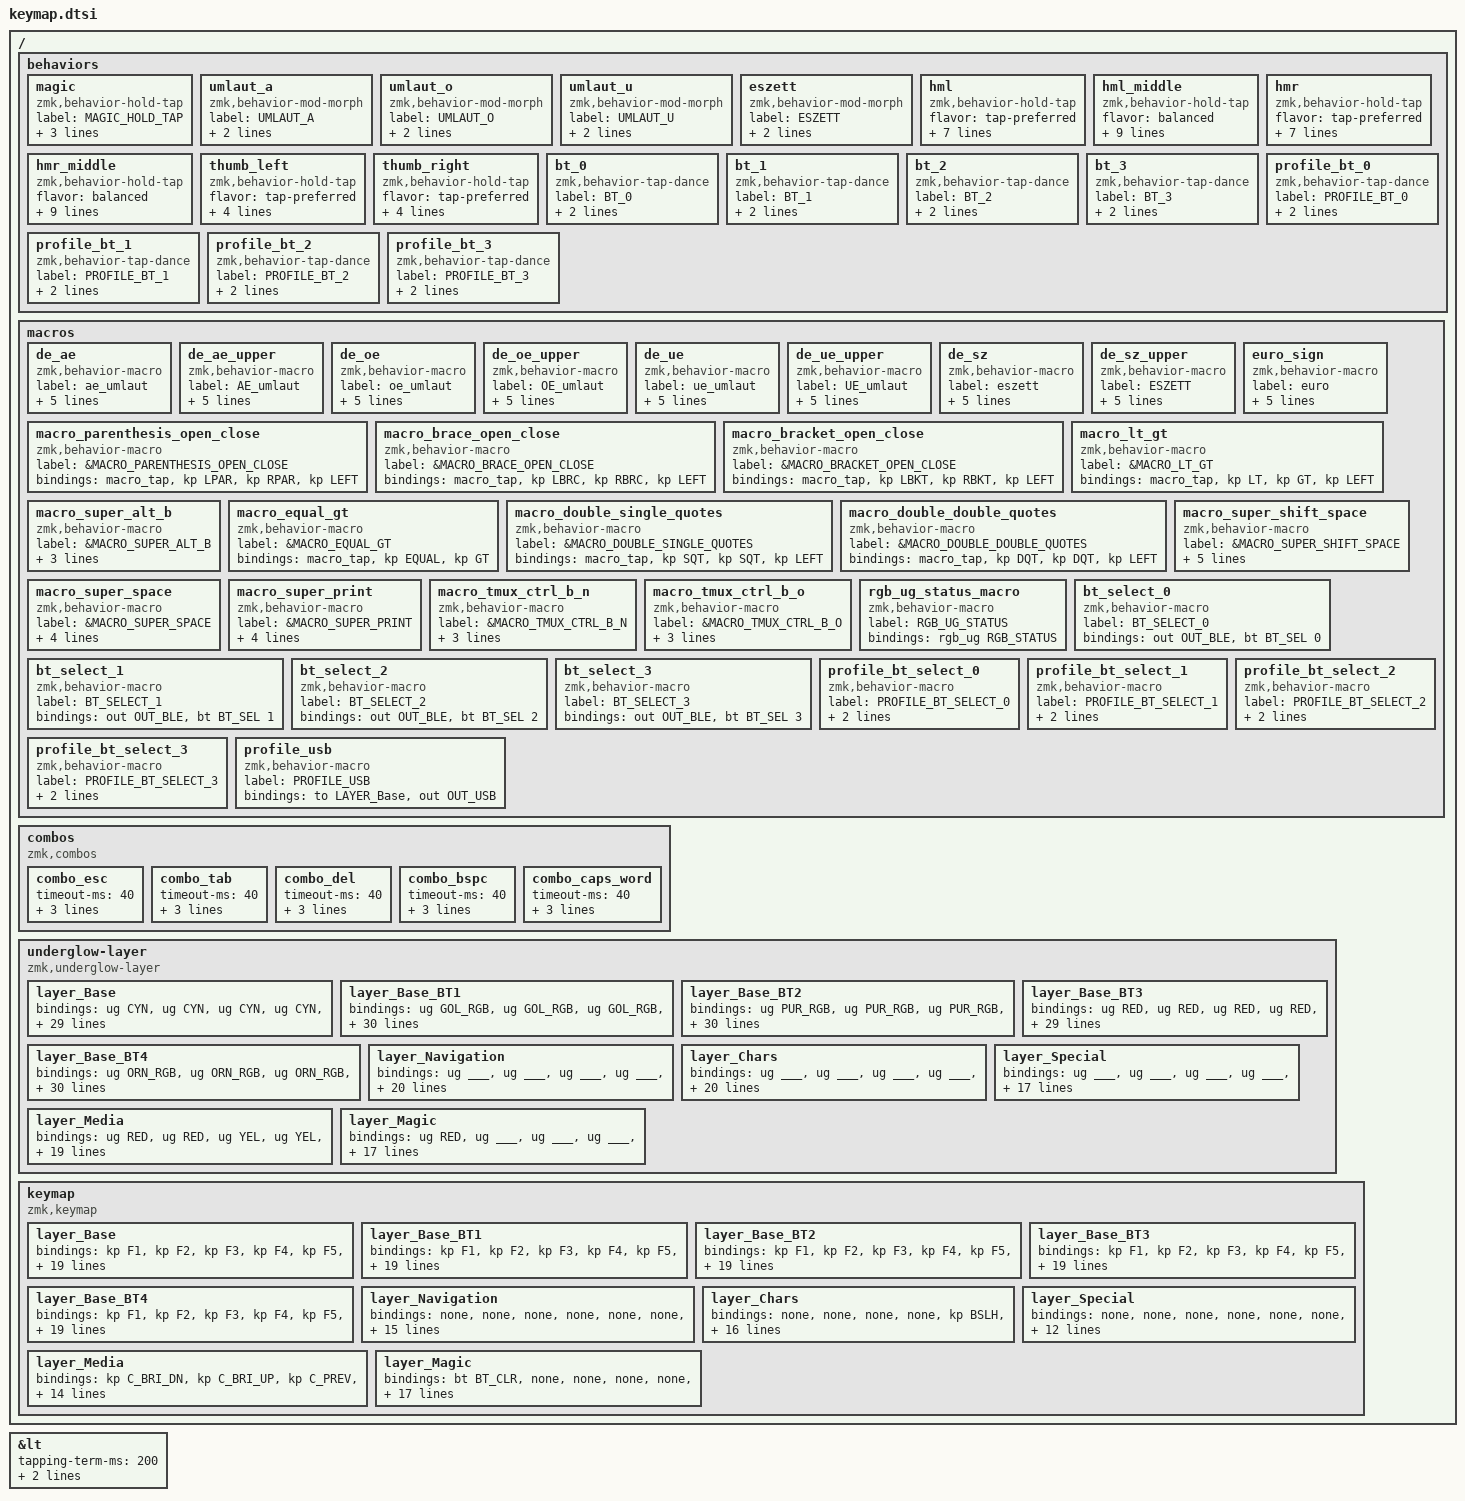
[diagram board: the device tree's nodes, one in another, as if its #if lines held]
/*
 * Copyright (c) 2020 The ZMK Contributors
 * SPDX-License-Identifier: MIT
 */

/* THIS FILE IS THE TEMPLATE - DO NOT EDIT DIRECTLY
 * The build process will generate the complete keymap
 * Edit config/layout.json and other config files instead
 */

#include <behaviors.dtsi>
#include <dt-bindings/zmk/keys.h>
#include <dt-bindings/zmk/bt.h>
#include <dt-bindings/zmk/outputs.h>
#include <dt-bindings/zmk/rgb.h>
#include <dt-bindings/zmk/rgb_colors.h>
#include <dt-bindings/zmk/pointing.h>

/* Helper Macros, based on https://github.com/urob/zmk-helpers/ */

#pragma once

#define ZMK_HELPER_STRINGIFY(x) #x

// Preprocessor mechanism to overload macros, cf. https://stackoverflow.com/a/27051616/6114651
#define VARGS_(_10, _9, _8, _7, _6, _5, _4, _3, _2, _1, N, ...) N
#define VARGS(...) VARGS_(__VA_ARGS__, 10, 9, 8, 7, 6, 5, 4, 3, 2, 1, 0)
#define CONCAT_(a, b) a##b
#define CONCAT(a, b) CONCAT_(a, b)

#define ZMK_BEHAVIOR_CORE_tap_dance  \
    compatible = "zmk,behavior-tap-dance"; \
    #binding-cells = <0>

#define ZMK_BEHAVIOR(name, type, ...) \
    name: name { \
        ZMK_BEHAVIOR_CORE_ ## type; \
        __VA_ARGS__ \
    };

#define ZMK_TAP_DANCE(name, ...) \
    ZMK_BEHAVIOR(name, tap_dance, __VA_ARGS__)

#define ZMK_TD_LAYER(name, layer) \
    ZMK_TAP_DANCE(name, \
        tapping-term-ms = <200>; \
        bindings = <&mo layer>, <&to layer>; \
)

/* Layer defines */
#define LAYER_Base 0
#define LAYER_Base_BT1 1
#define LAYER_Base_BT2 2
#define LAYER_Base_BT3 3
#define LAYER_Base_BT4 4
#define LAYER_Navigation 5
#define LAYER_Chars 6
#define LAYER_Special 7
#define LAYER_Media 8
#define LAYER_Magic 9

/* To deal with the situation where there is no Lower layer, to keep &lower happy */
#ifndef LAYER_Lower
#define LAYER_Lower 0
#endif

/* Custom color defines */
#define MAIN_RGB 0x00FF96
#define MAIN_HRM_RGB 0x00FFFF
#define MAIN_O_RGB 0x00FF78
#define COR_RGB 0xFF7C4D
#define ORN_RGB 0xFF8000
#define GDN_RGB 0xD9A521
#define GOL_RGB 0xFFD900
#define CHU_RGB 0x80FF00
#define SPG_RGB 0x00FF80
#define AZU_RGB 0x99F5FF
#define PUR_RGB 0x7A00FF
#define RED 0xFF0000
#define GRN 0x00FF00
#define BLU 0x0000FF
#define YEL 0xFFFF00
#define CYN 0x00FFFF
#define MAG 0xFF00FF
#define SAL_RGB 0xFFA082
#define ___ 0x000000

/* #define for key positions */
#define POS_LH_T1 52
#define POS_LH_T2 53
#define POS_LH_T3 54
#define POS_LH_T4 69
#define POS_LH_T5 70
#define POS_LH_T6 71
#define POS_LH_C1R2 15
#define POS_LH_C1R3 27
#define POS_LH_C1R4 39
#define POS_LH_C1R5 51
#define POS_LH_C2R1 4
#define POS_LH_C2R2 14
#define POS_LH_C2R3 26
#define POS_LH_C2R4 38
#define POS_LH_C2R5 50
#define POS_LH_C2R6 68
#define POS_LH_C3R1 3
#define POS_LH_C3R2 13
#define POS_LH_C3R3 25
#define POS_LH_C3R4 37
#define POS_LH_C3R5 49
#define POS_LH_C3R6 67
#define POS_LH_C4R1 2
#define POS_LH_C4R2 12
#define POS_LH_C4R3 24
#define POS_LH_C4R4 36
#define POS_LH_C4R5 48
#define POS_LH_C4R6 66
#define POS_LH_C5R1 1
#define POS_LH_C5R2 11
#define POS_LH_C5R3 23
#define POS_LH_C5R4 35
#define POS_LH_C5R5 47
#define POS_LH_C5R6 65
#define POS_LH_C6R1 0
#define POS_LH_C6R2 10
#define POS_LH_C6R3 22
#define POS_LH_C6R4 34
#define POS_LH_C6R5 46
#define POS_LH_C6R6 64
#define POS_RH_T1 57
#define POS_RH_T2 56
#define POS_RH_T3 55
#define POS_RH_T4 74
#define POS_RH_T5 73
#define POS_RH_T6 72
#define POS_RH_C1R2 16
#define POS_RH_C1R3 28
#define POS_RH_C1R4 40
#define POS_RH_C1R5 58
#define POS_RH_C2R1 5
#define POS_RH_C2R2 17
#define POS_RH_C2R3 29
#define POS_RH_C2R4 41
#define POS_RH_C2R5 59
#define POS_RH_C2R6 75
#define POS_RH_C3R1 6
#define POS_RH_C3R2 18
#define POS_RH_C3R3 30
#define POS_RH_C3R4 42
#define POS_RH_C3R5 60
#define POS_RH_C3R6 76
#define POS_RH_C4R1 7
#define POS_RH_C4R2 19
#define POS_RH_C4R3 31
#define POS_RH_C4R4 43
#define POS_RH_C4R5 61
#define POS_RH_C4R6 77
#define POS_RH_C5R1 8
#define POS_RH_C5R2 20
#define POS_RH_C5R3 32
#define POS_RH_C5R4 44
#define POS_RH_C5R5 62
#define POS_RH_C5R6 78
#define POS_RH_C6R1 9
#define POS_RH_C6R2 21
#define POS_RH_C6R3 33
#define POS_RH_C6R4 45
#define POS_RH_C6R5 63
#define POS_RH_C6R6 79

//
// Glove80 key positions index for positional hold-tap
// - https://discord.com/channels/877392805654306816/937645688244826154/1066713913351221248
// - https://media.discordapp.net/attachments/937645688244826154/1066713913133121556/image.png
//
// |------------------------|------------------------|
// | LEFT_HAND_KEYS         |        RIGHT_HAND_KEYS |
// |                        |                        |
// |  0  1  2  3  4         |          5  6  7  8  9 |
// | 10 11 12 13 14 15      |      16 17 18 19 20 21 |
// | 22 23 24 25 26 27      |      28 29 30 31 32 33 |
// | 34 35 36 37 38 39      |      40 41 42 43 44 45 |
// | 46 47 48 49 50 51      |      58 59 60 61 62 63 |
// | 64 65 66 67 68         |         75 76 77 78 79 |
// |                69 52   |   57 74                |
// |                 70 53  |  56 73                 |
// |                  71 54 | 55 72                  |
// |------------------------|------------------------|
//
#define LEFT_HAND_KEYS      \
        0  1  2  3  4       \
       10 11 12 13 14 15    \
       22 23 24 25 26 27    \
       34 35 36 37 38 39    \
       46 47 48 49 50 51    \
       64 65 66 67 68
#define RIGHT_HAND_KEYS     \
                                          5  6  7  8  9 \
                                      16 17 18 19 20 21 \
                                      28 29 30 31 32 33 \
                                      40 41 42 43 44 45 \
                                      58 59 60 61 62 63 \
                                         75 76 77 78 79
#define THUMB_KEYS          \
                      69 52       57 74                \
                       70 53     56 73                 \
                        71 54   55 72

/* Custom Device-tree */
// Adjust lt behavior
&lt {
  tapping-term-ms = <200>;  // Adjust this value (default is 200ms)
  quick-tap-ms = <150>;     // Allow quick repeated taps
  flavor = "balanced";      // Or "tap-preferred" or "hold-preferred"
};


/ {
    behaviors {
    ZMK_TD_LAYER(lower, LAYER_Lower)

    // Magic layer behavior
    magic: magic {
      compatible = "zmk,behavior-hold-tap";
      label = "MAGIC_HOLD_TAP";
      #binding-cells = <2>;
      flavor = "tap-preferred";
      tapping-term-ms = <200>;
      bindings = <&mo>, <&rgb_ug_status_macro>;
    };

    // Umlauts
    umlaut_a: umlaut_a {
      compatible = "zmk,behavior-mod-morph";
      label = "UMLAUT_A";
      #binding-cells = <0>;
      bindings = <&de_ae>, <&de_ae_upper>;
      mods = <(MOD_LSFT|MOD_RSFT)>;
    };

    umlaut_o: umlaut_o {
      compatible = "zmk,behavior-mod-morph";
      label = "UMLAUT_O";
      #binding-cells = <0>;
      bindings = <&de_oe>, <&de_oe_upper>;
      mods = <(MOD_LSFT|MOD_RSFT)>;
    };

    umlaut_u: umlaut_u {
      compatible = "zmk,behavior-mod-morph";
      label = "UMLAUT_U";
      #binding-cells = <0>;
      bindings = <&de_ue>, <&de_ue_upper>;
      mods = <(MOD_LSFT|MOD_RSFT)>;
    };

    eszett: eszett {
      compatible = "zmk,behavior-mod-morph";
      label = "ESZETT";
      #binding-cells = <0>;
      bindings = <&de_sz>, <&de_sz_upper>;
      mods = <(MOD_LSFT|MOD_RSFT)>;
    };

    // Home row mods - left hand
    hml: hml {
      compatible = "zmk,behavior-hold-tap";
      flavor = "tap-preferred";
      #binding-cells = <2>;
      tapping-term-ms = <200>;
      bindings = <&kp>, <&kp>;
      quick-tap-ms = <150>;
      require-prior-idle-ms = <0>;
      hold-trigger-key-positions = <RIGHT_HAND_KEYS THUMB_KEYS>;
      hold-trigger-on-release;
    };
    hml_middle: hml_middle {
      compatible = "zmk,behavior-hold-tap";
      flavor = "balanced";
      #binding-cells = <2>;
      tapping-term-ms = <200>;
      bindings = <&kp>, <&kp>;
      quick-tap-ms = <175>;
      require-prior-idle-ms = <50>;
      hold-trigger-key-positions = <RIGHT_HAND_KEYS THUMB_KEYS>;
      hold-trigger-on-release;
      hold-while-undecided;
      retro-tap;
    };

    // Home row mods - right hand
    hmr: hmr {
      compatible = "zmk,behavior-hold-tap";
      flavor = "tap-preferred";
      #binding-cells = <2>;
      tapping-term-ms = <200>;
      bindings = <&kp>, <&kp>;
      quick-tap-ms = <150>;
      require-prior-idle-ms = <0>;
      hold-trigger-key-positions = <LEFT_HAND_KEYS THUMB_KEYS>;
      hold-trigger-on-release;
    };
    hmr_middle: hmr_middle {
      compatible = "zmk,behavior-hold-tap";
      flavor = "balanced";
      #binding-cells = <2>;
      tapping-term-ms = <200>;
      bindings = <&kp>, <&kp>;
      quick-tap-ms = <175>;
      require-prior-idle-ms = <50>;
      hold-trigger-key-positions = <LEFT_HAND_KEYS THUMB_KEYS>;
      hold-trigger-on-release;
      hold-while-undecided;
      retro-tap;    
    };

    // Thumb layer keys - left
    thumb_left: thumb_left {
      compatible = "zmk,behavior-hold-tap";
      flavor = "tap-preferred";
      #binding-cells = <2>;
      tapping-term-ms = <200>;
      bindings = <&mo>, <&kp>;
      quick-tap-ms = <175>;
      require-prior-idle-ms = <75>;
    };

    // Thumb layer keys - right
    thumb_right: thumb_right {
      compatible = "zmk,behavior-hold-tap";
      flavor = "tap-preferred";
      #binding-cells = <2>;
      tapping-term-ms = <200>;
      bindings = <&mo>, <&kp>;
      quick-tap-ms = <175>;
      require-prior-idle-ms = <75>;
    };

#ifdef BT_DISC_CMD
    bt_0: bt_0 {
        compatible = "zmk,behavior-tap-dance";
        label = "BT_0";
        #binding-cells = <0>;
        tapping-term-ms = <200>;
        bindings = <&bt_select_0>, <&bt BT_DISC 0>;
    };
    bt_1: bt_1 {
        compatible = "zmk,behavior-tap-dance";
        label = "BT_1";
        #binding-cells = <0>;
        tapping-term-ms = <200>;
        bindings = <&bt_select_1>, <&bt BT_DISC 1>;
    };
    bt_2: bt_2 {
        compatible = "zmk,behavior-tap-dance";
        label = "BT_2";
        #binding-cells = <0>;
        tapping-term-ms = <200>;
        bindings = <&bt_select_2>, <&bt BT_DISC 2>;
    };
    bt_3: bt_3 {
        compatible = "zmk,behavior-tap-dance";
        label = "BT_3";
        #binding-cells = <0>;
        tapping-term-ms = <200>;
        bindings = <&bt_select_3>, <&bt BT_DISC 3>;
    };
#endif

#ifdef BT_DISC_CMD
    profile_bt_0: profile_bt_0 {
        compatible = "zmk,behavior-tap-dance";
        label = "PROFILE_BT_0";
        #binding-cells = <0>;
        tapping-term-ms = <200>;
        bindings = <&profile_bt_select_0>, <&bt BT_DISC 0>;
    };
    profile_bt_1: profile_bt_1 {
        compatible = "zmk,behavior-tap-dance";
        label = "PROFILE_BT_1";
        #binding-cells = <0>;
        tapping-term-ms = <200>;
        bindings = <&profile_bt_select_1>, <&bt BT_DISC 1>;
    };
    profile_bt_2: profile_bt_2 {
        compatible = "zmk,behavior-tap-dance";
        label = "PROFILE_BT_2";
        #binding-cells = <0>;
        tapping-term-ms = <200>;
        bindings = <&profile_bt_select_2>, <&bt BT_DISC 2>;
    };
    profile_bt_3: profile_bt_3 {
        compatible = "zmk,behavior-tap-dance";
        label = "PROFILE_BT_3";
        #binding-cells = <0>;
        tapping-term-ms = <200>;
        bindings = <&profile_bt_select_3>, <&bt BT_DISC 3>;
    };
#endif
};

    macros {
    ////////////////////////////////////////////////////////////////////////
    // German letters
    ////////////////////////////////////////////////////////////////////////
 
    de_ae: de_ae {
      compatible = "zmk,behavior-macro";
      label = "ae_umlaut";
      #binding-cells = <0>;
      wait-ms = <30>;
      tap-ms = <30>;
      bindings = 
        <&macro_tap &kp LC(LS(U))>,
        <&macro_tap &kp N0 &kp N0 &kp E &kp N4>,  // 00e4 is ä
        <&macro_tap &kp SPACE>;
    };

    de_ae_upper: de_ae_upper {
      compatible = "zmk,behavior-macro";
      label = "AE_umlaut";
      #binding-cells = <0>;
      wait-ms = <30>;
      tap-ms = <30>;
      bindings = 
        <&macro_tap &kp LC(LS(U))>,
        <&macro_tap &kp N0 &kp N0 &kp C &kp N4>,  // 00c4 is Ä
        <&macro_tap &kp SPACE>;
    };

    de_oe: de_oe {
      compatible = "zmk,behavior-macro";
      label = "oe_umlaut";
      #binding-cells = <0>;
      wait-ms = <30>;
      tap-ms = <30>;
      bindings = 
        <&macro_tap &kp LC(LS(U))>,
        <&macro_tap &kp N0 &kp N0 &kp F &kp N6>,  // 00f6 is ö
        <&macro_tap &kp SPACE>;
    };

    de_oe_upper: de_oe_upper {
      compatible = "zmk,behavior-macro";
      label = "OE_umlaut";
      #binding-cells = <0>;
      wait-ms = <30>;
      tap-ms = <30>;
      bindings = 
        <&macro_tap &kp LC(LS(U))>,
        <&macro_tap &kp N0 &kp N0 &kp D &kp N6>,  // 00d6 is Ö
        <&macro_tap &kp SPACE>;
    };

    de_ue: de_ue {
      compatible = "zmk,behavior-macro";
      label = "ue_umlaut";
      #binding-cells = <0>;
      wait-ms = <30>;
      tap-ms = <30>;
      bindings = 
        <&macro_tap &kp LC(LS(U))>,
        <&macro_tap &kp N0 &kp N0 &kp F &kp C>,  // 00fc is ü
        <&macro_tap &kp SPACE>;
    };

    de_ue_upper: de_ue_upper {
      compatible = "zmk,behavior-macro";
      label = "UE_umlaut";
      #binding-cells = <0>;
      wait-ms = <30>;
      tap-ms = <30>;
      bindings = 
        <&macro_tap &kp LC(LS(U))>,
        <&macro_tap &kp N0 &kp N0 &kp D &kp C>,  // 00dc is Ü
        <&macro_tap &kp SPACE>;
    };

    ////////////////////////////////////////////////////////////////////////
    // German SZ
    ////////////////////////////////////////////////////////////////////////

    de_sz: de_sz {
      compatible = "zmk,behavior-macro";
      label = "eszett";
      #binding-cells = <0>;
      wait-ms = <30>;
      tap-ms = <30>;
      bindings = 
        <&macro_tap &kp LC(LS(U))>,
        <&macro_tap &kp N0 &kp N0 &kp D &kp F>,  // 00df is ß
        <&macro_tap &kp SPACE>;
    };

    de_sz_upper: de_sz_upper {
      compatible = "zmk,behavior-macro";
      label = "ESZETT";
      #binding-cells = <0>;
      wait-ms = <30>;
      tap-ms = <30>;
      bindings = 
        <&macro_tap &kp LC(LS(U))>,
        <&macro_tap &kp N1 &kp E &kp N9 &kp E>,  // 1e9e is ẞ
        <&macro_tap &kp SPACE>;
    };

    ////////////////////////////////////////////////////////////////////////
    // Signs
    ////////////////////////////////////////////////////////////////////////

    euro_sign: euro_sign {
      compatible = "zmk,behavior-macro";
      label = "euro";
      #binding-cells = <0>;
      wait-ms = <30>;
      tap-ms = <30>;
      bindings = 
        <&macro_tap &kp LC(LS(U))>,
        <&macro_tap &kp N2 &kp N0 &kp A &kp C>,  // 20ac is €
        <&macro_tap &kp SPACE>;
    };

    macro_parenthesis_open_close: macro_parenthesis_open_close {
      label = "&MACRO_PARENTHESIS_OPEN_CLOSE";
      compatible = "zmk,behavior-macro";
      #binding-cells = <0>;
      bindings = 
        <&macro_tap>, 
        <&kp LPAR>, 
        <&kp RPAR>, 
        <&kp LEFT>;
    };

    macro_brace_open_close: macro_brace_open_close {
      label = "&MACRO_BRACE_OPEN_CLOSE";
      compatible = "zmk,behavior-macro";
      #binding-cells = <0>;
      bindings = 
        <&macro_tap>, 
        <&kp LBRC>, 
        <&kp RBRC>, 
        <&kp LEFT>;
    };

    macro_bracket_open_close: macro_bracket_open_close {
      label = "&MACRO_BRACKET_OPEN_CLOSE";
      compatible = "zmk,behavior-macro";
      #binding-cells = <0>;
      bindings = 
        <&macro_tap>, 
        <&kp LBKT>, 
        <&kp RBKT>, 
        <&kp LEFT>;
    };

    macro_lt_gt: macro_lt_gt {
      label = "&MACRO_LT_GT";
      compatible = "zmk,behavior-macro";
      #binding-cells = <0>;
      bindings = 
        <&macro_tap>, 
        <&kp LT>, 
        <&kp GT>, 
        <&kp LEFT>;
    };

    macro_super_alt_b: macro_super_alt_b {
      label = "&MACRO_SUPER_ALT_B";
      compatible = "zmk,behavior-macro";
      #binding-cells = <0>;
      bindings = 
        <&macro_press>, 
        <&kp LGUI>, 
        <&kp LALT>, 
        <&macro_tap>, 
        <&kp B>, 
        <&macro_release>, 
        <&kp LGUI>, 
        <&kp LALT>;
    };

    macro_equal_gt: macro_equal_gt {
      label = "&MACRO_EQUAL_GT";
      compatible = "zmk,behavior-macro";
      #binding-cells = <0>;
      bindings = 
        <&macro_tap>, 
        <&kp EQUAL>, 
        <&kp GT>;
    };

    macro_double_single_quotes: macro_double_single_quotes {
      label = "&MACRO_DOUBLE_SINGLE_QUOTES";
      compatible = "zmk,behavior-macro";
      #binding-cells = <0>;
      bindings = 
        <&macro_tap>, 
        <&kp SQT>, 
        <&kp SQT>, 
        <&kp LEFT>;
    };

    macro_double_double_quotes: macro_double_double_quotes {
      label = "&MACRO_DOUBLE_DOUBLE_QUOTES";
      compatible = "zmk,behavior-macro";
      #binding-cells = <0>;
      bindings = 
        <&macro_tap>, 
        <&kp DQT>, 
        <&kp DQT>, 
        <&kp LEFT>;
    };

    macro_super_shift_space: macro_super_shift_space {
      label = "&MACRO_SUPER_SHIFT_SPACE";
      compatible = "zmk,behavior-macro";
      #binding-cells = <0>;
      tap-ms = <30>;
      wait-ms = <15>;
      bindings = 
        <&macro_press>, 
        <&kp LGUI>, 
        <&kp LSHFT>, 
        <&macro_tap>, 
        <&kp SPACE>, 
        <&macro_release>, 
        <&kp LGUI>, 
        <&kp LSHFT>;
    };

    macro_super_space: macro_super_space {
      label = "&MACRO_SUPER_SPACE";
      compatible = "zmk,behavior-macro";
      #binding-cells = <0>;
      tap-ms = <30>;
      wait-ms = <15>;
      bindings = 
        <&macro_press>, 
        <&kp LGUI>, 
        <&macro_tap>, 
        <&kp SPACE>, 
        <&macro_release>, 
        <&kp LGUI>;
    };

    macro_super_print: macro_super_print {
      label = "&MACRO_SUPER_PRINT";
      compatible = "zmk,behavior-macro";
      #binding-cells = <0>;
      tap-ms = <30>;
      wait-ms = <15>;
      bindings = 
        <&macro_press>, 
        <&kp LGUI>, 
        <&macro_tap>, 
        <&kp PSCRN>, 
        <&macro_release>, 
        <&kp LGUI>;
    };

    macro_tmux_ctrl_b_n: macro_tmux_ctrl_b_n {
      label = "&MACRO_TMUX_CTRL_B_N";
      compatible = "zmk,behavior-macro";
      #binding-cells = <0>;
      bindings = 
        <&macro_press>, 
        <&kp RCTRL>, 
        <&macro_tap>, 
        <&kp B>, 
        <&macro_release>, 
        <&kp RCTRL>, 
        <&macro_tap>, 
        <&kp N>;
    };

    macro_tmux_ctrl_b_o: macro_tmux_ctrl_b_o {
      label = "&MACRO_TMUX_CTRL_B_O";
      compatible = "zmk,behavior-macro";
      #binding-cells = <0>;
      bindings = 
        <&macro_press>, 
        <&kp RCTRL>, 
        <&macro_tap>, 
        <&kp B>, 
        <&macro_release>, 
        <&kp RCTRL>, 
        <&macro_tap>, 
        <&kp O>;
    };

    // RGB status macro for magic layer
    rgb_ug_status_macro: rgb_ug_status_macro {
      label = "RGB_UG_STATUS";
      compatible = "zmk,behavior-macro";
      #binding-cells = <0>;
      bindings = <&rgb_ug RGB_STATUS>;
    };
    
#ifdef BT_DISC_CMD
    bt_select_0: bt_select_0 {
        label = "BT_SELECT_0";
        compatible = "zmk,behavior-macro";
        #binding-cells = <0>;
        bindings
            = <&out OUT_BLE>,
              <&bt BT_SEL 0>;
    };
    bt_select_1: bt_select_1 {
        label = "BT_SELECT_1";
        compatible = "zmk,behavior-macro";
        #binding-cells = <0>;
        bindings
            = <&out OUT_BLE>,
              <&bt BT_SEL 1>;
    };
    bt_select_2: bt_select_2 {
        label = "BT_SELECT_2";
        compatible = "zmk,behavior-macro";
        #binding-cells = <0>;
        bindings
            = <&out OUT_BLE>,
              <&bt BT_SEL 2>;
    };
    bt_select_3: bt_select_3 {
        label = "BT_SELECT_3";
        compatible = "zmk,behavior-macro";
        #binding-cells = <0>;
        bindings
            = <&out OUT_BLE>,
              <&bt BT_SEL 3>;
    };
#else
    bt_0: bt_0 {
        label = "BT_0";
        compatible = "zmk,behavior-macro";
        #binding-cells = <0>;
        bindings
            = <&out OUT_BLE>,
              <&bt BT_SEL 0>;
    };
    bt_1: bt_1 {
        label = "BT_1";
        compatible = "zmk,behavior-macro";
        #binding-cells = <0>;
        bindings
            = <&out OUT_BLE>,
              <&bt BT_SEL 1>;
    };
    bt_2: bt_2 {
        label = "BT_2";
        compatible = "zmk,behavior-macro";
        #binding-cells = <0>;
        bindings
            = <&out OUT_BLE>,
              <&bt BT_SEL 2>;
    };
    bt_3: bt_3 {
        label = "BT_3";
        compatible = "zmk,behavior-macro";
        #binding-cells = <0>;
        bindings
            = <&out OUT_BLE>,
              <&bt BT_SEL 3>;
    };
#endif

#ifdef BT_DISC_CMD
    profile_bt_select_0: profile_bt_select_0 {
        label = "PROFILE_BT_SELECT_0";
        compatible = "zmk,behavior-macro";
        #binding-cells = <0>;
        bindings
            = <&to LAYER_Base_BT1>,
              <&out OUT_BLE>,
              <&bt BT_SEL 0>;
    };
    profile_bt_select_1: profile_bt_select_1 {
        label = "PROFILE_BT_SELECT_1";
        compatible = "zmk,behavior-macro";
        #binding-cells = <0>;
        bindings
            = <&to LAYER_Base_BT2>,
              <&out OUT_BLE>,
              <&bt BT_SEL 1>;
    };
    profile_bt_select_2: profile_bt_select_2 {
        label = "PROFILE_BT_SELECT_2";
        compatible = "zmk,behavior-macro";
        #binding-cells = <0>;
        bindings
            = <&to LAYER_Base_BT3>,
              <&out OUT_BLE>,
              <&bt BT_SEL 2>;
    };
    profile_bt_select_3: profile_bt_select_3 {
        label = "PROFILE_BT_SELECT_3";
        compatible = "zmk,behavior-macro";
        #binding-cells = <0>;
        bindings
            = <&to LAYER_Base_BT4>,
              <&out OUT_BLE>,
              <&bt BT_SEL 3>;
    };
#else
    profile_bt_0: profile_bt_0 {
        label = "PROFILE_BT_0";
        compatible = "zmk,behavior-macro";
        #binding-cells = <0>;
        bindings
            = <&to LAYER_Base_BT1>,
              <&out OUT_BLE>,
              <&bt BT_SEL 0>;
    };
    profile_bt_1: profile_bt_1 {
        label = "PROFILE_BT_1";
        compatible = "zmk,behavior-macro";
        #binding-cells = <0>;
        bindings
            = <&to LAYER_Base_BT2>,
              <&out OUT_BLE>,
              <&bt BT_SEL 1>;
    };
    profile_bt_2: profile_bt_2 {
        label = "PROFILE_BT_2";
        compatible = "zmk,behavior-macro";
        #binding-cells = <0>;
        bindings
            = <&to LAYER_Base_BT3>,
              <&out OUT_BLE>,
              <&bt BT_SEL 2>;
    };
    profile_bt_3: profile_bt_3 {
        label = "PROFILE_BT_3";
        compatible = "zmk,behavior-macro";
        #binding-cells = <0>;
        bindings
            = <&to LAYER_Base_BT4>,
              <&out OUT_BLE>,
              <&bt BT_SEL 3>;
    };
#endif

    profile_usb: profile_usb {
        label = "PROFILE_USB";
        compatible = "zmk,behavior-macro";
        #binding-cells = <0>;
        bindings
            = <&to LAYER_Base>,
              <&out OUT_USB>;
    };
};

    combos {
        compatible = "zmk,combos";

        /* 1.1.2: J+K → Escape */
        combo_esc {
            timeout-ms = <40>;
            key-positions = <41 42>;
            bindings = <&kp ESC>;
            require-prior-idle-ms = <100>;
        };

        /* 1.1.4: D+F → Tab */
        combo_tab {
            timeout-ms = <40>;
            key-positions = <37 38>;
            bindings = <&kp TAB>;
            require-prior-idle-ms = <100>;
        };

        /* X+C → Delete */
        combo_del {
            timeout-ms = <40>;
            key-positions = <48 49>;
            bindings = <&kp DEL>;
            require-prior-idle-ms = <100>;
        };

        /* C+V → Backspace */
        combo_bspc {
            timeout-ms = <40>;
            key-positions = <49 50>;
            bindings = <&kp BSPC>;
            require-prior-idle-ms = <100>;
        };

        /* 1.3.3: Comma+Dot → Caps Word */
        combo_caps_word {
            timeout-ms = <40>;
            key-positions = <60 61>;
            bindings = <&caps_word>;
            require-prior-idle-ms = <100>;
        };
    };

        underglow-layer {
        compatible = "zmk,underglow-layer";

        layer_Base {
            bindings = <
                &ug CYN &ug CYN &ug CYN &ug CYN &ug CYN &ug CYN &ug CYN &ug CYN &ug CYN &ug CYN
                &ug MAIN_O_RGB &ug MAIN_RGB &ug MAIN_RGB &ug MAIN_RGB &ug MAIN_RGB &ug MAIN_RGB &ug MAIN_RGB &ug MAIN_RGB &ug MAIN_RGB &ug MAIN_RGB &ug MAIN_RGB &ug MAIN_O_RGB
                &ug MAIN_O_RGB &ug MAIN_RGB &ug MAIN_RGB &ug MAIN_RGB &ug MAIN_RGB &ug MAIN_RGB &ug MAIN_RGB &ug MAIN_RGB &ug MAIN_RGB &ug MAIN_RGB &ug MAIN_RGB &ug MAIN_O_RGB
                &ug MAIN_O_RGB &ug MAIN_HRM_RGB &ug MAIN_HRM_RGB &ug MAIN_HRM_RGB &ug MAIN_HRM_RGB &ug MAIN_RGB &ug MAIN_RGB &ug MAIN_HRM_RGB &ug MAIN_HRM_RGB &ug MAIN_HRM_RGB &ug MAIN_HRM_RGB &ug MAIN_O_RGB
                &ug MAIN_O_RGB &ug MAIN_RGB &ug MAIN_RGB &ug MAIN_RGB &ug MAIN_RGB &ug MAIN_RGB &ug MAIN_O_RGB &ug MAIN_O_RGB &ug MAIN_O_RGB &ug MAIN_O_RGB &ug SAL_RGB &ug SAL_RGB &ug MAIN_RGB &ug MAIN_RGB &ug MAIN_O_RGB &ug MAIN_O_RGB &ug MAIN_O_RGB &ug MAIN_O_RGB
                &ug MAIN_O_RGB &ug MAIN_O_RGB &ug MAIN_O_RGB &ug MAIN_O_RGB &ug MAIN_O_RGB &ug MAIN_HRM_RGB &ug MAIN_HRM_RGB &ug MAIN_O_RGB &ug MAIN_O_RGB &ug MAIN_HRM_RGB &ug MAIN_HRM_RGB &ug MAIN_O_RGB &ug MAIN_O_RGB &ug MAIN_O_RGB &ug MAIN_O_RGB &ug MAIN_O_RGB
            >;
            layer-id = <0>;
        };

        layer_Base_BT1 {
            bindings = <
                &ug GOL_RGB &ug GOL_RGB &ug GOL_RGB &ug GOL_RGB &ug GOL_RGB &ug GOL_RGB &ug GOL_RGB &ug GOL_RGB &ug GOL_RGB &ug GOL_RGB
                &ug MAIN_O_RGB &ug MAIN_RGB &ug MAIN_RGB &ug MAIN_RGB &ug MAIN_RGB &ug MAIN_RGB &ug MAIN_RGB &ug MAIN_RGB &ug MAIN_RGB &ug MAIN_RGB &ug MAIN_RGB &ug MAIN_O_RGB
                &ug MAIN_O_RGB &ug MAIN_RGB &ug MAIN_RGB &ug MAIN_RGB &ug MAIN_RGB &ug MAIN_RGB &ug MAIN_RGB &ug MAIN_RGB &ug MAIN_RGB &ug MAIN_RGB &ug MAIN_RGB &ug MAIN_O_RGB
                &ug MAIN_O_RGB &ug MAIN_HRM_RGB &ug MAIN_HRM_RGB &ug MAIN_HRM_RGB &ug MAIN_HRM_RGB &ug MAIN_RGB &ug MAIN_RGB &ug MAIN_HRM_RGB &ug MAIN_HRM_RGB &ug MAIN_HRM_RGB &ug MAIN_HRM_RGB &ug MAIN_O_RGB
                &ug MAIN_O_RGB &ug MAIN_RGB &ug MAIN_RGB &ug MAIN_RGB &ug MAIN_RGB &ug MAIN_RGB &ug MAIN_O_RGB &ug MAIN_O_RGB &ug MAIN_O_RGB &ug MAIN_O_RGB &ug SAL_RGB &ug SAL_RGB &ug MAIN_RGB &ug MAIN_RGB &ug MAIN_O_RGB &ug MAIN_O_RGB &ug MAIN_O_RGB &ug MAIN_O_RGB
                &ug MAIN_O_RGB &ug MAIN_O_RGB &ug MAIN_O_RGB &ug MAIN_O_RGB &ug MAIN_O_RGB &ug MAIN_HRM_RGB &ug MAIN_HRM_RGB &ug MAIN_O_RGB &ug MAIN_O_RGB &ug MAIN_HRM_RGB &ug MAIN_HRM_RGB &ug MAIN_O_RGB &ug MAIN_O_RGB &ug MAIN_O_RGB &ug MAIN_O_RGB &ug MAIN_O_RGB
            >;
            layer-id = <1>;
        };

        layer_Base_BT2 {
            bindings = <
                &ug PUR_RGB &ug PUR_RGB &ug PUR_RGB &ug PUR_RGB &ug PUR_RGB &ug PUR_RGB &ug PUR_RGB &ug PUR_RGB &ug PUR_RGB &ug PUR_RGB
                &ug MAIN_O_RGB &ug MAIN_RGB &ug MAIN_RGB &ug MAIN_RGB &ug MAIN_RGB &ug MAIN_RGB &ug MAIN_RGB &ug MAIN_RGB &ug MAIN_RGB &ug MAIN_RGB &ug MAIN_RGB &ug MAIN_O_RGB
                &ug MAIN_O_RGB &ug MAIN_RGB &ug MAIN_RGB &ug MAIN_RGB &ug MAIN_RGB &ug MAIN_RGB &ug MAIN_RGB &ug MAIN_RGB &ug MAIN_RGB &ug MAIN_RGB &ug MAIN_RGB &ug MAIN_O_RGB
                &ug MAIN_O_RGB &ug MAIN_HRM_RGB &ug MAIN_HRM_RGB &ug MAIN_HRM_RGB &ug MAIN_HRM_RGB &ug MAIN_RGB &ug MAIN_RGB &ug MAIN_HRM_RGB &ug MAIN_HRM_RGB &ug MAIN_HRM_RGB &ug MAIN_HRM_RGB &ug MAIN_O_RGB
                &ug MAIN_O_RGB &ug MAIN_RGB &ug MAIN_RGB &ug MAIN_RGB &ug MAIN_RGB &ug MAIN_RGB &ug MAIN_O_RGB &ug MAIN_O_RGB &ug MAIN_O_RGB &ug MAIN_O_RGB &ug SAL_RGB &ug SAL_RGB &ug MAIN_RGB &ug MAIN_RGB &ug MAIN_O_RGB &ug MAIN_O_RGB &ug MAIN_O_RGB &ug MAIN_O_RGB
                &ug MAIN_O_RGB &ug MAIN_O_RGB &ug MAIN_O_RGB &ug MAIN_O_RGB &ug MAIN_O_RGB &ug MAIN_HRM_RGB &ug MAIN_HRM_RGB &ug MAIN_O_RGB &ug MAIN_O_RGB &ug MAIN_HRM_RGB &ug MAIN_HRM_RGB &ug MAIN_O_RGB &ug MAIN_O_RGB &ug MAIN_O_RGB &ug MAIN_O_RGB &ug MAIN_O_RGB
            >;
            layer-id = <2>;
        };

        layer_Base_BT3 {
            bindings = <
                &ug RED &ug RED &ug RED &ug RED &ug RED &ug RED &ug RED &ug RED &ug RED &ug RED
                &ug MAIN_O_RGB &ug MAIN_RGB &ug MAIN_RGB &ug MAIN_RGB &ug MAIN_RGB &ug MAIN_RGB &ug MAIN_RGB &ug MAIN_RGB &ug MAIN_RGB &ug MAIN_RGB &ug MAIN_RGB &ug MAIN_O_RGB
                &ug MAIN_O_RGB &ug MAIN_RGB &ug MAIN_RGB &ug MAIN_RGB &ug MAIN_RGB &ug MAIN_RGB &ug MAIN_RGB &ug MAIN_RGB &ug MAIN_RGB &ug MAIN_RGB &ug MAIN_RGB &ug MAIN_O_RGB
                &ug MAIN_O_RGB &ug MAIN_HRM_RGB &ug MAIN_HRM_RGB &ug MAIN_HRM_RGB &ug MAIN_HRM_RGB &ug MAIN_RGB &ug MAIN_RGB &ug MAIN_HRM_RGB &ug MAIN_HRM_RGB &ug MAIN_HRM_RGB &ug MAIN_HRM_RGB &ug MAIN_O_RGB
                &ug MAIN_O_RGB &ug MAIN_RGB &ug MAIN_RGB &ug MAIN_RGB &ug MAIN_RGB &ug MAIN_RGB &ug MAIN_O_RGB &ug MAIN_O_RGB &ug MAIN_O_RGB &ug MAIN_O_RGB &ug SAL_RGB &ug SAL_RGB &ug MAIN_RGB &ug MAIN_RGB &ug MAIN_O_RGB &ug MAIN_O_RGB &ug MAIN_O_RGB &ug MAIN_O_RGB
                &ug MAIN_O_RGB &ug MAIN_O_RGB &ug MAIN_O_RGB &ug MAIN_O_RGB &ug MAIN_O_RGB &ug MAIN_HRM_RGB &ug MAIN_HRM_RGB &ug MAIN_O_RGB &ug MAIN_O_RGB &ug MAIN_HRM_RGB &ug MAIN_HRM_RGB &ug MAIN_O_RGB &ug MAIN_O_RGB &ug MAIN_O_RGB &ug MAIN_O_RGB &ug MAIN_O_RGB
            >;
            layer-id = <3>;
        };

        layer_Base_BT4 {
            bindings = <
                &ug ORN_RGB &ug ORN_RGB &ug ORN_RGB &ug ORN_RGB &ug ORN_RGB &ug ORN_RGB &ug ORN_RGB &ug ORN_RGB &ug ORN_RGB &ug ORN_RGB
                &ug MAIN_O_RGB &ug MAIN_RGB &ug MAIN_RGB &ug MAIN_RGB &ug MAIN_RGB &ug MAIN_RGB &ug MAIN_RGB &ug MAIN_RGB &ug MAIN_RGB &ug MAIN_RGB &ug MAIN_RGB &ug MAIN_O_RGB
                &ug MAIN_O_RGB &ug MAIN_RGB &ug MAIN_RGB &ug MAIN_RGB &ug MAIN_RGB &ug MAIN_RGB &ug MAIN_RGB &ug MAIN_RGB &ug MAIN_RGB &ug MAIN_RGB &ug MAIN_RGB &ug MAIN_O_RGB
                &ug MAIN_O_RGB &ug MAIN_HRM_RGB &ug MAIN_HRM_RGB &ug MAIN_HRM_RGB &ug MAIN_HRM_RGB &ug MAIN_RGB &ug MAIN_RGB &ug MAIN_HRM_RGB &ug MAIN_HRM_RGB &ug MAIN_HRM_RGB &ug MAIN_HRM_RGB &ug MAIN_O_RGB
                &ug MAIN_O_RGB &ug MAIN_RGB &ug MAIN_RGB &ug MAIN_RGB &ug MAIN_RGB &ug MAIN_RGB &ug MAIN_O_RGB &ug MAIN_O_RGB &ug MAIN_O_RGB &ug MAIN_O_RGB &ug SAL_RGB &ug SAL_RGB &ug MAIN_RGB &ug MAIN_RGB &ug MAIN_O_RGB &ug MAIN_O_RGB &ug MAIN_O_RGB &ug MAIN_O_RGB
                &ug MAIN_O_RGB &ug MAIN_O_RGB &ug MAIN_O_RGB &ug MAIN_O_RGB &ug MAIN_O_RGB &ug MAIN_HRM_RGB &ug MAIN_HRM_RGB &ug MAIN_O_RGB &ug MAIN_O_RGB &ug MAIN_HRM_RGB &ug MAIN_HRM_RGB &ug MAIN_O_RGB &ug MAIN_O_RGB &ug MAIN_O_RGB &ug MAIN_O_RGB &ug MAIN_O_RGB
            >;
            layer-id = <4>;
        };

        layer_Navigation {
            bindings = <
                &ug ___ &ug ___ &ug ___ &ug ___ &ug ___ &ug ___ &ug ___ &ug ___ &ug ___ &ug ___
                &ug ___ &ug ___ &ug ___ &ug ___ &ug ___ &ug ___ &ug ___ &ug ___ &ug ___ &ug ___ &ug ___ &ug ___
                &ug ___ &ug ___ &ug ___ &ug ___ &ug ___ &ug ___ &ug ___ &ug ___ &ug ___ &ug ___ &ug COR_RGB &ug COR_RGB
                &ug ___ &ug MAIN_HRM_RGB &ug MAIN_HRM_RGB &ug MAIN_HRM_RGB &ug MAIN_HRM_RGB &ug ___ &ug AZU_RGB &ug AZU_RGB &ug AZU_RGB &ug AZU_RGB &ug COR_RGB &ug COR_RGB
                &ug ___ &ug ___ &ug ___ &ug ___ &ug ___ &ug ___ &ug ___ &ug ___ &ug ___ &ug GDN_RGB &ug SAL_RGB &ug SAL_RGB &ug ___ &ug ___ &ug ___ &ug ___ &ug ___ &ug CHU_RGB
                &ug ___ &ug ___ &ug ___ &ug ___ &ug ___ &ug MAG &ug ___ &ug ___ &ug MAIN_O_RGB &ug MAIN_O_RGB &ug MAIN_RGB &ug GDN_RGB &ug GDN_RGB &ug CHU_RGB &ug CHU_RGB &ug CHU_RGB
            >;
            layer-id = <5>;
        };

        layer_Chars {
            bindings = <
                &ug ___ &ug ___ &ug ___ &ug ___ &ug SPG_RGB &ug ___ &ug ___ &ug ___ &ug ___ &ug ___
                &ug MAIN_RGB &ug MAIN_RGB &ug BLU &ug BLU &ug SPG_RGB &ug SPG_RGB &ug ___ &ug ___ &ug ___ &ug ___ &ug ___ &ug ___
                &ug YEL &ug BLU &ug ORN_RGB &ug ORN_RGB &ug BLU &ug YEL &ug ___ &ug YEL &ug YEL &ug ___ &ug ___ &ug ___
                &ug YEL &ug YEL &ug MAIN_RGB &ug MAIN_RGB &ug YEL &ug YEL &ug AZU_RGB &ug AZU_RGB &ug AZU_RGB &ug AZU_RGB &ug ___ &ug ___
                &ug MAIN_RGB &ug BLU &ug MAIN_RGB &ug MAIN_RGB &ug BLU &ug YEL &ug ___ &ug ___ &ug ___ &ug ___ &ug SAL_RGB &ug SAL_RGB &ug ___ &ug MAIN_RGB &ug ___ &ug ___ &ug ___ &ug ___
                &ug ___ &ug MAIN_RGB &ug BLU &ug BLU &ug MAIN_RGB &ug MAIN_RGB &ug ___ &ug MAIN_RGB &ug MAIN_O_RGB &ug MAIN_O_RGB &ug MAG &ug ___ &ug MAIN_RGB &ug MAIN_RGB &ug ___ &ug ___
            >;
            layer-id = <6>;
        };

        layer_Special {
            bindings = <
                &ug ___ &ug ___ &ug ___ &ug ___ &ug ___ &ug ___ &ug ___ &ug ___ &ug ___ &ug ___
                &ug ___ &ug ___ &ug ___ &ug ___ &ug ___ &ug ___ &ug ___ &ug ___ &ug ___ &ug ___ &ug ___ &ug ___
                &ug ___ &ug ___ &ug ___ &ug GRN &ug ___ &ug ___ &ug ___ &ug GRN &ug ___ &ug GRN &ug ___ &ug ___
                &ug ___ &ug GRN &ug GRN &ug ___ &ug ___ &ug ___ &ug AZU_RGB &ug AZU_RGB &ug AZU_RGB &ug AZU_RGB &ug ___ &ug ___
                &ug ___ &ug ___ &ug ___ &ug ___ &ug ___ &ug ___ &ug ___ &ug ___ &ug ___ &ug ___ &ug SAL_RGB &ug SAL_RGB &ug ___ &ug ___ &ug ___ &ug ___ &ug ___ &ug ___
                &ug ___ &ug ___ &ug ___ &ug ___ &ug ___ &ug ___ &ug CYN &ug ___ &ug MAIN_O_RGB &ug MAIN_O_RGB &ug ___ &ug ___ &ug ___ &ug ___ &ug ___ &ug ___
            >;
            layer-id = <7>;
        };

        layer_Media {
            bindings = <
                &ug RED &ug RED &ug YEL &ug YEL &ug YEL &ug ___ &ug ___ &ug ___ &ug MAIN_RGB &ug MAIN_RGB
                &ug ___ &ug ___ &ug ORN_RGB &ug ORN_RGB &ug ORN_RGB &ug BLU &ug ___ &ug ___ &ug ___ &ug ___ &ug ___ &ug ___
                &ug BLU &ug BLU &ug MAIN_RGB &ug MAIN_RGB &ug MAIN_RGB &ug BLU &ug BLU &ug ___ &ug ___ &ug ___ &ug ___ &ug ___
                &ug ___ &ug ___ &ug MAIN_RGB &ug MAIN_RGB &ug MAIN_RGB &ug BLU &ug AZU_RGB &ug AZU_RGB &ug AZU_RGB &ug AZU_RGB &ug ___ &ug ___
                &ug ___ &ug ___ &ug MAIN_RGB &ug MAIN_RGB &ug MAIN_RGB &ug BLU &ug ___ &ug BLU &ug ___ &ug ___ &ug SAL_RGB &ug SAL_RGB &ug ___ &ug ___ &ug ___ &ug ___ &ug ___ &ug ___
                &ug ___ &ug ___ &ug ___ &ug MAIN_RGB &ug BLU &ug MAIN_RGB &ug ___ &ug MAIN_RGB &ug MAIN_O_RGB &ug MAG &ug BLU &ug ___ &ug ___ &ug ___ &ug ___ &ug ___
            >;
            layer-id = <8>;
        };

        layer_Magic {
            bindings = <
                &ug RED &ug ___ &ug ___ &ug ___ &ug ___ &ug ___ &ug ___ &ug ___ &ug ___ &ug RED
                &ug ___ &ug ___ &ug ___ &ug ___ &ug ___ &ug ___ &ug ___ &ug ___ &ug ___ &ug ___ &ug ___ &ug ___
                &ug ___ &ug GRN &ug GRN &ug GRN &ug GRN &ug GOL_RGB &ug ___ &ug ___ &ug ___ &ug ___ &ug ___ &ug ___
                &ug RED &ug COR_RGB &ug COR_RGB &ug COR_RGB &ug COR_RGB &ug PUR_RGB &ug ___ &ug ___ &ug ___ &ug ___ &ug ___ &ug RED
                &ug RED &ug ___ &ug ___ &ug ___ &ug ___ &ug ___ &ug ___ &ug ___ &ug ___ &ug BLU &ug BLU &ug ORN_RGB &ug ___ &ug ___ &ug ___ &ug ___ &ug ___ &ug RED
                &ug ___ &ug ___ &ug ___ &ug ___ &ug ___ &ug RED &ug ___ &ug ___ &ug BLU &ug BLU &ug ___ &ug ___ &ug ___ &ug ___ &ug ___ &ug ___
            >;
            layer-id = <9>;
        };
    };

    keymap {
        compatible = "zmk,keymap";

        layer_Base {
            bindings = <
                &kp F1 &kp F2 &kp F3 &kp F4 &kp F5 &kp F6 &kp F7 &kp F8 &kp F9 &kp F10
                &kp GRAVE &kp N1 &kp N2 &kp N3 &kp N4 &kp N5 &kp N6 &kp N7 &kp N8 &kp N9 &kp N0 &kp MINUS
                &kp HOME &kp Q &kp W &kp E &kp R &kp T &kp Y &kp U &kp I &kp O &kp P &kp BSLH
                &kp ESC &hml LGUI A &hml LALT S &hml_middle LSHFT D &hml LCTRL F &kp G &kp H &hmr RCTRL J &hmr_middle RSHFT K &hmr LALT L &hmr RGUI SEMI &kp SQT
                &kp LSHFT &kp Z &kp X &kp C &kp V &kp B &kp ESC &magic LAYER_Magic 0 &kp UP &kp F13 &kp DEL &kp BSPC &kp N &kp M &kp COMMA &kp DOT &kp FSLH &kp PG_UP
                &kp LEFT &kp RIGHT &kp FSLH &kp COMMA &kp DOT &thumb_left LAYER_Navigation SPACE &mo LAYER_Special &kp DOWN &kp RSHFT &lt LAYER_Media TAB &thumb_right LAYER_Chars RET &none &kp RALT &kp LBKT &kp RBKT &kp PG_DN
            >;
        };

        layer_Base_BT1 {
            bindings = <
                &kp F1 &kp F2 &kp F3 &kp F4 &kp F5 &kp F6 &kp F7 &kp F8 &kp F9 &kp F10
                &kp GRAVE &kp N1 &kp N2 &kp N3 &kp N4 &kp N5 &kp N6 &kp N7 &kp N8 &kp N9 &kp N0 &kp MINUS
                &kp HOME &kp Q &kp W &kp E &kp R &kp T &kp Y &kp U &kp I &kp O &kp P &kp BSLH
                &kp ESC &hml LGUI A &hml LALT S &hml_middle LSHFT D &hml LCTRL F &kp G &kp H &hmr RCTRL J &hmr_middle RSHFT K &hmr LALT L &hmr RGUI SEMI &kp SQT
                &kp LSHFT &kp Z &kp X &kp C &kp V &kp B &kp ESC &magic LAYER_Magic 0 &kp UP &kp F13 &kp DEL &kp BSPC &kp N &kp M &kp COMMA &kp DOT &kp FSLH &kp PG_UP
                &kp LEFT &kp RIGHT &kp FSLH &kp COMMA &kp DOT &thumb_left LAYER_Navigation SPACE &mo LAYER_Special &kp DOWN &kp RSHFT &lt LAYER_Media TAB &thumb_right LAYER_Chars RET &none &kp RALT &kp LBKT &kp RBKT &kp PG_DN
            >;
        };

        layer_Base_BT2 {
            bindings = <
                &kp F1 &kp F2 &kp F3 &kp F4 &kp F5 &kp F6 &kp F7 &kp F8 &kp F9 &kp F10
                &kp GRAVE &kp N1 &kp N2 &kp N3 &kp N4 &kp N5 &kp N6 &kp N7 &kp N8 &kp N9 &kp N0 &kp MINUS
                &kp HOME &kp Q &kp W &kp E &kp R &kp T &kp Y &kp U &kp I &kp O &kp P &kp BSLH
                &kp ESC &hml LGUI A &hml LALT S &hml_middle LSHFT D &hml LCTRL F &kp G &kp H &hmr RCTRL J &hmr_middle RSHFT K &hmr LALT L &hmr RGUI SEMI &kp SQT
                &kp LSHFT &kp Z &kp X &kp C &kp V &kp B &kp ESC &magic LAYER_Magic 0 &kp UP &kp F13 &kp DEL &kp BSPC &kp N &kp M &kp COMMA &kp DOT &kp FSLH &kp PG_UP
                &kp LEFT &kp RIGHT &kp FSLH &kp COMMA &kp DOT &thumb_left LAYER_Navigation SPACE &mo LAYER_Special &kp DOWN &kp RSHFT &lt LAYER_Media TAB &thumb_right LAYER_Chars RET &none &kp RALT &kp LBKT &kp RBKT &kp PG_DN
            >;
        };

        layer_Base_BT3 {
            bindings = <
                &kp F1 &kp F2 &kp F3 &kp F4 &kp F5 &kp F6 &kp F7 &kp F8 &kp F9 &kp F10
                &kp GRAVE &kp N1 &kp N2 &kp N3 &kp N4 &kp N5 &kp N6 &kp N7 &kp N8 &kp N9 &kp N0 &kp MINUS
                &kp HOME &kp Q &kp W &kp E &kp R &kp T &kp Y &kp U &kp I &kp O &kp P &kp BSLH
                &kp ESC &hml LGUI A &hml LALT S &hml_middle LSHFT D &hml LCTRL F &kp G &kp H &hmr RCTRL J &hmr_middle RSHFT K &hmr LALT L &hmr RGUI SEMI &kp SQT
                &kp LSHFT &kp Z &kp X &kp C &kp V &kp B &kp ESC &magic LAYER_Magic 0 &kp UP &kp F13 &kp DEL &kp BSPC &kp N &kp M &kp COMMA &kp DOT &kp FSLH &kp PG_UP
                &kp LEFT &kp RIGHT &kp FSLH &kp COMMA &kp DOT &thumb_left LAYER_Navigation SPACE &mo LAYER_Special &kp DOWN &kp RSHFT &lt LAYER_Media TAB &thumb_right LAYER_Chars RET &none &kp RALT &kp LBKT &kp RBKT &kp PG_DN
            >;
        };

        layer_Base_BT4 {
            bindings = <
                &kp F1 &kp F2 &kp F3 &kp F4 &kp F5 &kp F6 &kp F7 &kp F8 &kp F9 &kp F10
                &kp GRAVE &kp N1 &kp N2 &kp N3 &kp N4 &kp N5 &kp N6 &kp N7 &kp N8 &kp N9 &kp N0 &kp MINUS
                &kp HOME &kp Q &kp W &kp E &kp R &kp T &kp Y &kp U &kp I &kp O &kp P &kp BSLH
                &kp ESC &hml LGUI A &hml LALT S &hml_middle LSHFT D &hml LCTRL F &kp G &kp H &hmr RCTRL J &hmr_middle RSHFT K &hmr LALT L &hmr RGUI SEMI &kp SQT
                &kp LSHFT &kp Z &kp X &kp C &kp V &kp B &kp ESC &magic LAYER_Magic 0 &kp UP &kp F13 &kp DEL &kp BSPC &kp N &kp M &kp COMMA &kp DOT &kp FSLH &kp PG_UP
                &kp LEFT &kp RIGHT &kp FSLH &kp COMMA &kp DOT &thumb_left LAYER_Navigation SPACE &mo LAYER_Special &kp DOWN &kp RSHFT &lt LAYER_Media TAB &thumb_right LAYER_Chars RET &none &kp RALT &kp LBKT &kp RBKT &kp PG_DN
            >;
        };

        layer_Navigation {
            bindings = <
                &none &none &none &none &none &none &none &none &none &none
                &none &none &none &none &none &none &none &none &none &none &none &none
                &none &none &none &none &none &none &none &none &none &none &kp LS(LG(EQUAL)) &kp LG(EQUAL)
                &none &kp LGUI &kp LALT &kp LSHFT &kp LCTRL &none &kp LEFT &kp DOWN &kp UP &kp RIGHT &kp LS(LG(MINUS)) &kp LG(MINUS)
                &none &none &none &none &none &none &none &none &none &kp F14 &kp DEL &kp BSPC &none &none &none &none &none &msc SCRL_UP
                &none &none &none &none &none &mo LAYER_Navigation &none &none &kp RSHFT &kp TAB &kp RET &macro_super_print &kp PSCRN &msc SCRL_LEFT &msc SCRL_RIGHT &msc SCRL_DOWN
            >;
        };

        layer_Chars {
            bindings = <
                &none &none &none &none &kp BSLH &none &none &none &none &none
                &kp GRAVE &kp EXCL &kp LPAR &kp RPAR &kp SEMI &kp COMMA &none &none &none &none &none &none
                &kp PRCNT &kp LBRC &kp SQT &kp DQT &kp RBRC &kp QMARK &none &kp COLON &kp AT &none &none &none
                &kp HASH &hml LGUI CARET &hml LALT EQUAL &hml_middle LSHFT MINUS &hml LCTRL DLLR &kp ASTRK &kp LEFT &kp DOWN &kp UP &kp RIGHT &none &none
                &kp TILDE &kp LT &kp PIPE &kp UNDER &kp GT &kp FSLH &none &none &none &none &kp DEL &kp BSPC &none &kp RCTRL &none &none &none &none
                &none &kp AMPS &kp LBKT &kp RBKT &kp PLUS &kp SPACE &none &kp ESC &kp RSHFT &kp TAB &mo LAYER_Chars &none &kp RET &kp TAB &none &none
            >;
        };

        layer_Special {
            bindings = <
                &none &none &none &none &none &none &none &none &none &none
                &none &none &none &none &none &none &none &none &none &none &none &none
                &none &none &none &euro_sign &none &none &none &umlaut_u &none &umlaut_o &none &none
                &none &umlaut_a &eszett &none &none &none &kp LEFT &kp DOWN &kp UP &kp RIGHT &none &none
                &none &none &none &none &none &none &none &none &none &none &kp DEL &kp BSPC &none &none &none &none &none &none
                &none &none &none &none &none &none &mo LAYER_Special &none &kp RSHFT &kp TAB &none &none &none &none &none &none
            >;
        };

        layer_Media {
            bindings = <
                &kp C_BRI_DN &kp C_BRI_UP &kp C_PREV &kp C_PP &kp C_NEXT &none &none &none &kp F11 &kp F12
                &none &none &kp C_VOL_DN &kp C_MUTE &kp C_VOL_UP &kp COMMA &none &none &none &none &none &none
                &kp LPAR &kp RPAR &kp N7 &kp N8 &kp N9 &kp MINUS &kp EQUAL &none &none &none &none &none
                &none &none &kp N4 &kp N5 &kp N6 &kp ASTRK &kp LEFT &kp DOWN &kp UP &kp RIGHT &none &none
                &none &none &kp N1 &kp N2 &kp N3 &kp FSLH &none &kp DOT &none &none &kp DEL &kp BSPC &none &none &none &none &none &none
                &none &none &none &kp N0 &kp PLUS &kp SPACE &none &kp ESC &kp RSHFT &mo LAYER_Media &kp RET &none &none &none &none &none
            >;
        };

        layer_Magic {
            bindings = <
                &bt BT_CLR &none &none &none &none &none &none &none &none &bt BT_CLR_ALL
                &none &none &none &none &none &none &none &none &none &none &none &none
                &none &rgb_ug RGB_SPI &rgb_ug RGB_SAI &rgb_ug RGB_HUI &rgb_ug RGB_BRI &rgb_ug RGB_TOG &none &none &none &none &none &none
                &bootloader &rgb_ug RGB_SPD &rgb_ug RGB_SAD &rgb_ug RGB_HUD &rgb_ug RGB_BRD &rgb_ug RGB_EFF &none &none &none &none &none &bootloader
                &sys_reset &none &none &none &none &none &none &none &none &profile_bt_2 &profile_bt_3 &profile_usb &none &none &none &none &none &sys_reset
                &none &none &none &none &none &sys_reset &none &none &profile_bt_0 &profile_bt_1 &none &none &none &none &none &none
            >;
        };
    };
};

